# HDMI_WP_L3_MAIN register map
Vendor: Texas Instruments
Peripheral module from a debugger description file (folder DRA72x).
Registers are 32-bit, access per field, reset 0x0 unless marked. A register's access mark holds for its fields unless they carry their own. Offsets are as the file gives them; lines under a group give offsets from that group; [hi:lo] are bit positions; {n}, {i} and the like mark numbered series; 'fields as' and 'values as' point back to an identical list; <NAME> marks a mode.

## HDMI_WP_L3_MAIN
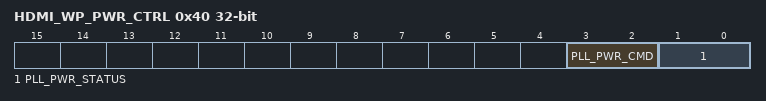
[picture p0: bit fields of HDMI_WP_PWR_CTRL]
0x40 HDMI_WP_PWR_CTRL — Power control
  [3:2] PLL_PWR_CMD rw — Command for power control of the HDMI PLL Control module
    0=STATE_OFF (Command to change to OFF state (PLL_PWR_CMD_OFF signal)); 1=STATE_ON_HSCLK (Command to change to ON state for PLL (DCOCLK is power down) (PLL_PWR_CMD_ON_HS_CLK signal)); 3=STATE_ON_DIV (Command to change to ON state for PLL (no DCOCLKLDO/CLKDCOLDO clock output to the HDMI-PHY) (PLL_PWR_CMD_ON_DIV signal)); 2=STATE_ON_ALL (Command to change to ON state for PLL (PLL_PWR_CMD_ON_ALL signal))
  [1:0] PLL_PWR_STATUS ro — Status of the power control of the HDMI PLL Control module
    0=STATE_OFF (HDMI PLL Control module in OFF state); 1=STATE_ON_HSCLK (HDMI PLL Control module in ON state for PLL); 3=STATE_ON_DIV (HDMI PLL Control module in ON state for PLL (no clock output to the HDMI-PHY)); 2=STATE_ON_ALL (HDMI PLL Control module in ON state for PLL)
0x70 HDMI_WP_CLK — Configuration of clocks
  [10:8] SCP_PWR_DIV rw — Defines the divisor value to be used for the generation of the SCP_PWR clock (up to 66.5MHz) from the input interface clock (up to 266MHz). 0x0 means gated 0x1 means free-running The valid values are from 0 to 7. In case of interface access to register through SCP interface, if the SCP_PWR clock is gated, the HW automatically generates the clock by using a divisor of 7 and updates the bit-field with the value 7. It is then software responsibility to change the value at any time in order to improve SCP latency when accessing the registers in the HDMI_PHY and PLLCTRL_HDMI by reducing the value.
